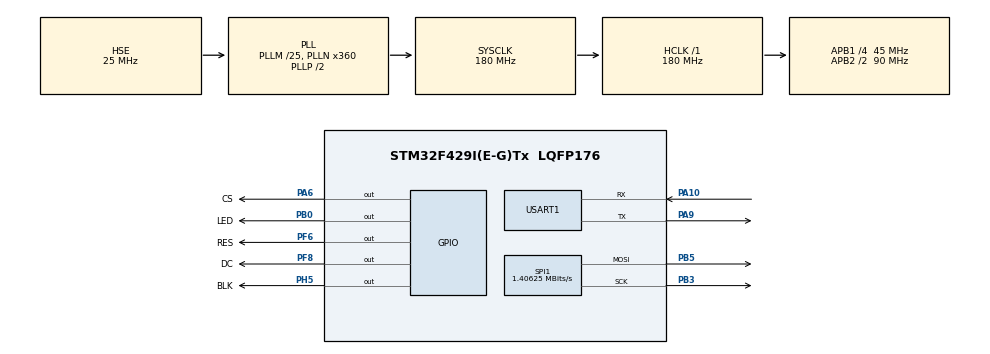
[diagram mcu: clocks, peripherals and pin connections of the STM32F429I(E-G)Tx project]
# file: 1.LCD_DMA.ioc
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Dma.Request0=SPI1_TX
Dma.SPI1_TX.0.Direction=DMA_MEMORY_TO_PERIPH
Dma.SPI1_TX.0.FIFOMode=DMA_FIFOMODE_DISABLE
Dma.SPI1_TX.0.Instance=DMA2_Stream3
Dma.SPI1_TX.0.MemDataAlignment=DMA_MDATAALIGN_HALFWORD
Dma.SPI1_TX.0.MemInc=DMA_MINC_DISABLE
Dma.SPI1_TX.0.Mode=DMA_NORMAL
Dma.SPI1_TX.0.PeriphDataAlignment=DMA_PDATAALIGN_HALFWORD
Dma.SPI1_TX.0.PeriphInc=DMA_PINC_DISABLE
Dma.SPI1_TX.0.Priority=DMA_PRIORITY_LOW
Mcu.Family=STM32F4
Mcu.Name=STM32F429I(E-G)Tx
Mcu.Package=LQFP176
NVIC.DMA2_Stream3_IRQn=true\:0\:0\:false\:false\:true\:false\:true\:true
NVIC.PriorityGroup=NVIC_PRIORITYGROUP_4
PA10.Mode=Asynchronous
PA10.Signal=USART1_RX
PA13.Mode=Serial_Wire
PA13.Signal=SYS_JTMS-SWDIO
PA14.Mode=Serial_Wire
PA14.Signal=SYS_JTCK-SWCLK
PA6.GPIO_Label=CS
PA6.GPIO_Speed=GPIO_SPEED_FREQ_HIGH
PA6.Signal=GPIO_Output
PA9.Mode=Asynchronous
PA9.Signal=USART1_TX
PB0.GPIO_Label=LED
PB0.Signal=GPIO_Output
PB3.Mode=TX_Only_Simplex_Unidirect_Master
PB3.Signal=SPI1_SCK
PB5.Mode=TX_Only_Simplex_Unidirect_Master
PB5.Signal=SPI1_MOSI
PC14/OSC32_IN.Mode=LSE-External-Oscillator
PC14/OSC32_IN.Signal=RCC_OSC32_IN
PC15/OSC32_OUT.Mode=LSE-External-Oscillator
PC15/OSC32_OUT.Signal=RCC_OSC32_OUT
PF6.GPIO_Label=RES
PF6.GPIO_Speed=GPIO_SPEED_FREQ_HIGH
PF6.PinState=GPIO_PIN_SET
PF6.Signal=GPIO_Output
PF8.GPIO_Label=DC
PF8.GPIO_Speed=GPIO_SPEED_FREQ_HIGH
PF8.Signal=GPIO_Output
PH0/OSC_IN.Mode=HSE-External-Oscillator
PH0/OSC_IN.Signal=RCC_OSC_IN
PH1/OSC_OUT.Mode=HSE-External-Oscillator
PH1/OSC_OUT.Signal=RCC_OSC_OUT
PH5.GPIO_Label=BLK
PH5.GPIO_Speed=GPIO_SPEED_FREQ_HIGH
PH5.PinState=GPIO_PIN_SET
PH5.Signal=GPIO_Output
ProjectManager.HeapSize=0x200
ProjectManager.StackSize=0x400
ProjectManager.TargetToolchain=MDK-ARM V5
RCC.48MHZClocksFreq_Value=90000000
RCC.AHBFreq_Value=180000000
RCC.APB1CLKDivider=RCC_HCLK_DIV4
RCC.APB1Freq_Value=45000000
RCC.APB1TimFreq_Value=90000000
RCC.APB2CLKDivider=RCC_HCLK_DIV2
RCC.APB2Freq_Value=90000000
RCC.APB2TimFreq_Value=180000000
RCC.CortexFreq_Value=180000000
RCC.HCLKFreq_Value=180000000
RCC.HSE_VALUE=25000000
RCC.HSI_VALUE=16000000
RCC.PLLM=25
RCC.PLLN=360
RCC.PLLSourceVirtual=RCC_PLLSOURCE_HSE
RCC.SYSCLKFreq_VALUE=180000000
RCC.SYSCLKSource=RCC_SYSCLKSOURCE_PLLCLK
RCC.VCOOutputFreq_Value=360000000
SPI1.BaudRatePrescaler=SPI_BAUDRATEPRESCALER_64
SPI1.CLKPhase=SPI_PHASE_2EDGE
SPI1.CLKPolarity=SPI_POLARITY_HIGH
SPI1.CalculateBaudRate=1.40625 MBits/s
SPI1.Direction=SPI_DIRECTION_2LINES
SPI1.Mode=SPI_MODE_MASTER
SPI1.VirtualType=VM_MASTER
USART1.VirtualMode=VM_ASYNC
board=custom

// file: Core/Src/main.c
/* USER CODE BEGIN Header */
/**
  ******************************************************************************
  * @file           : main.c
  * @brief          : Main program body
  ******************************************************************************
  * @attention
  *
  * Copyright (c) 2023 STMicroelectronics.
  * All rights reserved.
  *
  * This software is licensed under terms that can be found in the LICENSE file
  * in the root directory of this software component.
  * If no LICENSE file comes with this software, it is provided AS-IS.
  *
  ******************************************************************************
  */
/* USER CODE END Header */
#include "main.h"
#include "dma.h"
#include "spi.h"
#include "usart.h"
#include "gpio.h"

/* USER CODE BEGIN Includes */
#include "lcd.h"
#include "pic.h"
/* USER CODE END Includes */

void SystemClock_Config(void);

int main(void)
{
	/* USER CODE BEGIN 1 */
    uint8_t i,j;
	float t=0;
	/* USER CODE END 1 */

	/* MCU Configuration--------------------------------------------------------*/

	/* Reset of all peripherals, Initializes the Flash interface and the Systick. */
	HAL_Init();

	/* Configure the system clock */
	SystemClock_Config();

	/* Initialize all configured peripherals */
	MX_GPIO_Init();
	MX_DMA_Init();
	MX_SPI1_Init();
	MX_USART1_UART_Init();
	/* USER CODE BEGIN 2 */
    LCD_Init();//LCD初始化
	LCD_Fill(0,0,LCD_W,LCD_H,WHITE);
	/* USER CODE END 2 */

	/* Infinite loop */
	while (1)
	{
		LCD_ShowPicture(0,0,240,240,gImage_2);
		HAL_Delay(1000);
		LCD_Fill(0,0,LCD_W,LCD_H,WHITE);
		LCD_ShowChinese(0,0,(uint8_t*)"中景园电子",RED,WHITE,32,0);
		LCD_ShowString(0,40,(uint8_t*)"LCD_W:",RED,WHITE,16,0);
		LCD_ShowIntNum(48,40,LCD_W,3,RED,WHITE,16);
		LCD_ShowString(80,40,(uint8_t*)"LCD_H:",RED,WHITE,16,0);
		LCD_ShowIntNum(128,40,LCD_H,3,RED,WHITE,16);
		LCD_ShowString(80,40,(uint8_t*)"LCD_H:",RED,WHITE,16,0);
		LCD_ShowString(0,70,(uint8_t*)"Increaseing Nun:",RED,WHITE,16,0);
		LCD_ShowFloatNum1(128,70,t,4,RED,WHITE,16);
		t+=0.11;
		for(j=0;j<3;j++)
		{
			for(i=0;i<6;i++)
			{
				LCD_ShowPicture(40*i,120+j*40,40,40,gImage_1);
			}
		}
		HAL_Delay(1000);
		LCD_Fill(0,0,LCD_W,LCD_H,WHITE);
	}
}

void SystemClock_Config(void)
{
  RCC_OscInitTypeDef RCC_OscInitStruct = {0};
  RCC_ClkInitTypeDef RCC_ClkInitStruct = {0};

  /** Configure the main internal regulator output voltage
  */
  __HAL_RCC_PWR_CLK_ENABLE();
  __HAL_PWR_VOLTAGESCALING_CONFIG(PWR_REGULATOR_VOLTAGE_SCALE1);

  /** Initializes the RCC Oscillators according to the specified parameters
  * in the RCC_OscInitTypeDef structure.
  */
  RCC_OscInitStruct.OscillatorType = RCC_OSCILLATORTYPE_HSE;
  RCC_OscInitStruct.HSEState = RCC_HSE_ON;
  RCC_OscInitStruct.PLL.PLLState = RCC_PLL_ON;
  RCC_OscInitStruct.PLL.PLLSource = RCC_PLLSOURCE_HSE;
  RCC_OscInitStruct.PLL.PLLM = 25;
  RCC_OscInitStruct.PLL.PLLN = 360;
  RCC_OscInitStruct.PLL.PLLP = RCC_PLLP_DIV2;
  RCC_OscInitStruct.PLL.PLLQ = 4;
  if (HAL_RCC_OscConfig(&RCC_OscInitStruct) != HAL_OK)
  {
    Error_Handler();
  }

  /** Activate the Over-Drive mode
  */
  if (HAL_PWREx_EnableOverDrive() != HAL_OK)
  {
    Error_Handler();
  }

  /** Initializes the CPU, AHB and APB buses clocks
  */
  RCC_ClkInitStruct.ClockType = RCC_CLOCKTYPE_HCLK|RCC_CLOCKTYPE_SYSCLK
                              |RCC_CLOCKTYPE_PCLK1|RCC_CLOCKTYPE_PCLK2;
  RCC_ClkInitStruct.SYSCLKSource = RCC_SYSCLKSOURCE_PLLCLK;
  RCC_ClkInitStruct.AHBCLKDivider = RCC_SYSCLK_DIV1;
  RCC_ClkInitStruct.APB1CLKDivider = RCC_HCLK_DIV4;
  RCC_ClkInitStruct.APB2CLKDivider = RCC_HCLK_DIV2;

  if (HAL_RCC_ClockConfig(&RCC_ClkInitStruct, FLASH_LATENCY_5) != HAL_OK)
  {
    Error_Handler();
  }
}

void Error_Handler(void)
{
  __disable_irq();
  while (1)
  {
  }
}
